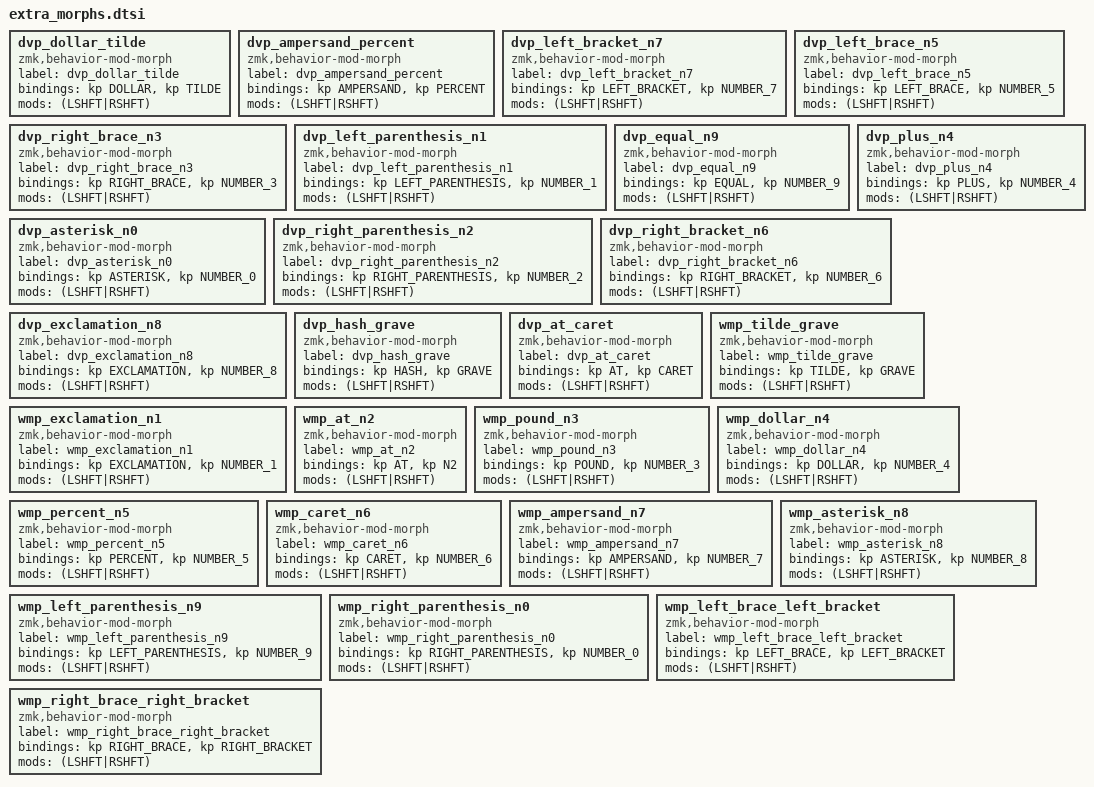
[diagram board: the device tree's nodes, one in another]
dvp_dollar_tilde: dvp_dollar_tilde {
    compatible = "zmk,behavior-mod-morph";
    label = "dvp_dollar_tilde";
    #binding-cells = <0>;
    bindings = <&kp DOLLAR>, <&kp TILDE>;
    mods = <(LSHFT|RSHFT)>;
};
dvp_ampersand_percent: dvp_ampersand_percent {
    compatible = "zmk,behavior-mod-morph";
    label = "dvp_ampersand_percent";
    #binding-cells = <0>;
    bindings = <&kp AMPERSAND>, <&kp PERCENT>;
    mods = <(LSHFT|RSHFT)>;
};
dvp_left_bracket_n7: dvp_left_bracket_n7 {
    compatible = "zmk,behavior-mod-morph";
    label = "dvp_left_bracket_n7";
    #binding-cells = <0>;
    bindings = <&kp LEFT_BRACKET>, <&kp NUMBER_7>;
    mods = <(LSHFT|RSHFT)>;
};
dvp_left_brace_n5: dvp_left_brace_n5 {
    compatible = "zmk,behavior-mod-morph";
    label = "dvp_left_brace_n5";
    #binding-cells = <0>;
    bindings = <&kp LEFT_BRACE>, <&kp NUMBER_5>;
    mods = <(LSHFT|RSHFT)>;
};
dvp_right_brace_n3: dvp_right_brace_n3 {
    compatible = "zmk,behavior-mod-morph";
    label = "dvp_right_brace_n3";
    #binding-cells = <0>;
    bindings = <&kp RIGHT_BRACE>, <&kp NUMBER_3>;
    mods = <(LSHFT|RSHFT)>;
};
dvp_left_parenthesis_n1: dvp_left_parenthesis_n1 {
    compatible = "zmk,behavior-mod-morph";
    label = "dvp_left_parenthesis_n1";
    #binding-cells = <0>;
    bindings = <&kp LEFT_PARENTHESIS>, <&kp NUMBER_1>;
    mods = <(LSHFT|RSHFT)>;
};
dvp_equal_n9: dvp_equal_n9 {
    compatible = "zmk,behavior-mod-morph";
    label = "dvp_equal_n9";
    #binding-cells = <0>;
    bindings = <&kp EQUAL>, <&kp NUMBER_9>;
    mods = <(LSHFT|RSHFT)>;
};
dvp_asterisk_n0: dvp_asterisk_n0 {
    compatible = "zmk,behavior-mod-morph";
    label = "dvp_asterisk_n0";
    #binding-cells = <0>;
    bindings = <&kp ASTERISK>, <&kp NUMBER_0>;
    mods = <(LSHFT|RSHFT)>;
};
dvp_right_parenthesis_n2: dvp_right_parenthesis_n2 {
    compatible = "zmk,behavior-mod-morph";
    label = "dvp_right_parenthesis_n2";
    #binding-cells = <0>;
    bindings = <&kp RIGHT_PARENTHESIS>, <&kp NUMBER_2>;
    mods = <(LSHFT|RSHFT)>;
};
dvp_plus_n4: dvp_plus_n4 {
    compatible = "zmk,behavior-mod-morph";
    label = "dvp_plus_n4";
    #binding-cells = <0>;
    bindings = <&kp PLUS>, <&kp NUMBER_4>;
    mods = <(LSHFT|RSHFT)>;
};
dvp_right_bracket_n6: dvp_right_bracket_n6 {
    compatible = "zmk,behavior-mod-morph";
    label = "dvp_right_bracket_n6";
    #binding-cells = <0>;
    bindings = <&kp RIGHT_BRACKET>, <&kp NUMBER_6>;
    mods = <(LSHFT|RSHFT)>;
};
dvp_exclamation_n8: dvp_exclamation_n8 {
    compatible = "zmk,behavior-mod-morph";
    label = "dvp_exclamation_n8";
    #binding-cells = <0>;
    bindings = <&kp EXCLAMATION>, <&kp NUMBER_8>;
    mods = <(LSHFT|RSHFT)>;
};
dvp_hash_grave: dvp_hash_grave {
    compatible = "zmk,behavior-mod-morph";
    label = "dvp_hash_grave";
    #binding-cells = <0>;
    bindings = <&kp HASH>, <&kp GRAVE>;
    mods = <(LSHFT|RSHFT)>;
};
dvp_at_caret: dvp_at_caret {
    compatible = "zmk,behavior-mod-morph";
    label = "dvp_at_caret";
    #binding-cells = <0>;
    bindings = <&kp AT>, <&kp CARET>;
    mods = <(LSHFT|RSHFT)>;
};
wmp_tilde_grave: wmp_tilde_grave {
    compatible = "zmk,behavior-mod-morph";
    label = "wmp_tilde_grave";
    #binding-cells = <0>;
    bindings = <&kp TILDE>, <&kp GRAVE>;
    mods = <(LSHFT|RSHFT)>;
};
wmp_exclamation_n1: wmp_exclamation_n1 {
    compatible = "zmk,behavior-mod-morph";
    label = "wmp_exclamation_n1";
    #binding-cells = <0>;
    bindings = <&kp EXCLAMATION>, <&kp NUMBER_1>;
    mods = <(LSHFT|RSHFT)>;
};
wmp_at_n2: wmp_at_n2 {
    compatible = "zmk,behavior-mod-morph";
    label = "wmp_at_n2";
    #binding-cells = <0>;
    bindings = <&kp AT>, <&kp N2>;
    mods = <(LSHFT|RSHFT)>;
};
wmp_pound_n3: wmp_pound_n3 {
    compatible = "zmk,behavior-mod-morph";
    label = "wmp_pound_n3";
    #binding-cells = <0>;
    bindings = <&kp POUND>, <&kp NUMBER_3>;
    mods = <(LSHFT|RSHFT)>;
};
wmp_dollar_n4: wmp_dollar_n4 {
    compatible = "zmk,behavior-mod-morph";
    label = "wmp_dollar_n4";
    #binding-cells = <0>;
    bindings = <&kp DOLLAR>, <&kp NUMBER_4>;
    mods = <(LSHFT|RSHFT)>;
};
wmp_percent_n5: wmp_percent_n5 {
    compatible = "zmk,behavior-mod-morph";
    label = "wmp_percent_n5";
    #binding-cells = <0>;
    bindings = <&kp PERCENT>, <&kp NUMBER_5>;
    mods = <(LSHFT|RSHFT)>;
};
wmp_caret_n6: wmp_caret_n6 {
    compatible = "zmk,behavior-mod-morph";
    label = "wmp_caret_n6";
    #binding-cells = <0>;
    bindings = <&kp CARET>, <&kp NUMBER_6>;
    mods = <(LSHFT|RSHFT)>;
};
wmp_ampersand_n7: wmp_ampersand_n7 {
    compatible = "zmk,behavior-mod-morph";
    label = "wmp_ampersand_n7";
    #binding-cells = <0>;
    bindings = <&kp AMPERSAND>, <&kp NUMBER_7>;
    mods = <(LSHFT|RSHFT)>;
};
wmp_asterisk_n8: wmp_asterisk_n8 {
    compatible = "zmk,behavior-mod-morph";
    label = "wmp_asterisk_n8";
    #binding-cells = <0>;
    bindings = <&kp ASTERISK>, <&kp NUMBER_8>;
    mods = <(LSHFT|RSHFT)>;
};
wmp_left_parenthesis_n9: wmp_left_parenthesis_n9 {
    compatible = "zmk,behavior-mod-morph";
    label = "wmp_left_parenthesis_n9";
    #binding-cells = <0>;
    bindings = <&kp LEFT_PARENTHESIS>, <&kp NUMBER_9>;
    mods = <(LSHFT|RSHFT)>;
};
wmp_right_parenthesis_n0: wmp_right_parenthesis_n0 {
    compatible = "zmk,behavior-mod-morph";
    label = "wmp_right_parenthesis_n0";
    #binding-cells = <0>;
    bindings = <&kp RIGHT_PARENTHESIS>, <&kp NUMBER_0>;
    mods = <(LSHFT|RSHFT)>;
};
wmp_left_brace_left_bracket: wmp_left_brace_left_bracket {
    compatible = "zmk,behavior-mod-morph";
    label = "wmp_left_brace_left_bracket";
    #binding-cells = <0>;
    bindings = <&kp LEFT_BRACE>, <&kp LEFT_BRACKET>;
    mods = <(LSHFT|RSHFT)>;
};
wmp_right_brace_right_bracket: wmp_right_brace_right_bracket {
    compatible = "zmk,behavior-mod-morph";
    label = "wmp_right_brace_right_bracket";
    #binding-cells = <0>;
    bindings = <&kp RIGHT_BRACE>, <&kp RIGHT_BRACKET>;
    mods = <(LSHFT|RSHFT)>;
};
